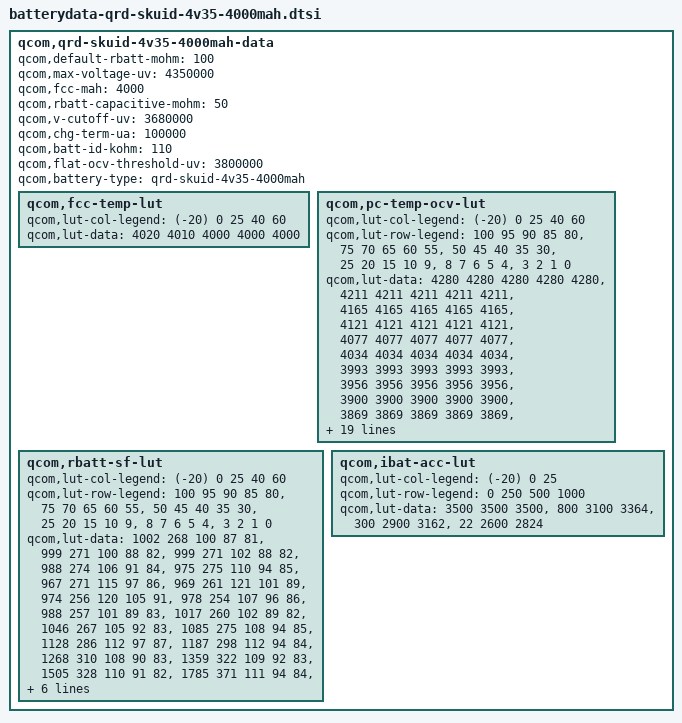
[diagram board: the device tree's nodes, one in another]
/* Copyright (c) 2014, The Linux Foundation. All rights reserved.
 *
 * This program is free software; you can redistribute it and/or modify
 * it under the terms of the GNU General Public License version 2 and
 * only version 2 as published by the Free Software Foundation.
 *
 * This program is distributed in the hope that it will be useful,
 * but WITHOUT ANY WARRANTY; without even the implied warranty of
 * MERCHANTABILITY or FITNESS FOR A PARTICULAR PURPOSE.  See the
 * GNU General Public License for more details.
 */


qcom,qrd-skuid-4v35-4000mah-data {
	qcom,default-rbatt-mohm = <100>;//<188>;
	qcom,max-voltage-uv = <4350000>;
	qcom,fcc-mah = <4000>;
	qcom,rbatt-capacitive-mohm = <50>;
	qcom,v-cutoff-uv = <3680000>;
	qcom,chg-term-ua = <100000>;
	qcom,batt-id-kohm = <110>;
	qcom,flat-ocv-threshold-uv = <3800000>;
	qcom,battery-type = "qrd-skuid-4v35-4000mah";

	qcom,fcc-temp-lut {
		qcom,lut-col-legend = <(-20) 0 25 40 60>;
		qcom,lut-data = <4020 4010 4000 4000 4000>;
	};

	qcom,pc-temp-ocv-lut {
		qcom,lut-col-legend = <(-20) 0 25 40 60>;
		qcom,lut-row-legend = <100 95 90 85 80>,
				<75 70 65 60 55>,
				<50 45 40 35 30>,
				<25 20 15 10 9>,
				<8 7 6 5 4>,
				<3 2 1 0>;
		/*qcom,lut-data = <4280 4280 4280 4280 4280>,
				<4202 4202 4202 4202 4202>,
				<4147 4147 4147 4147 4147>,
				<4095 4095 4095 4095 4095>,
				<4044 4044 4044 4044 4044>,
				<3993 3993 3993 3993 3993>,
				<3946 3946 3946 3946 3946>,
				<3887 3887 3887 3887 3887>,
				<3852 3852 3852 3852 3852>,
				<3815 3815 3815 3815 3815>,
				<3784 3784 3784 3784 3784>,
				<3758 3758 3758 3758 3758>,
				<3735 3735 3735 3735 3735>,
				<3714 3714 3714 3714 3714>,
				<3696 3696 3696 3696 3696>,
				<3681 3681 3681 3681 3681>,
				<3667 3667 3667 3667 3667>,
				<3644 3644 3644 3644 3644>,
				<3613 3613 3613 3613 3613>,
				<3610 3610 3610 3610 3610>,
				<3607 3607 3607 3607 3607>,
				<3605 3605 3605 3605 3605>,
				<3602 3602 3602 3602 3602>,
				<3600 3600 3600 3600 3600>,
				<3593 3593 3593 3593 3593>,
				<3586 3586 3586 3586 3586>,
				<3573 3573 3573 3573 3573>,
				<3549 3549 3549 3549 3549>,
				<3500 3500 3500 3500 3500>;
				*/
			qcom,lut-data = <4280 4280 4280 4280 4280>,
				<4211 4211 4211 4211 4211>,
				<4165 4165 4165 4165 4165>,
				<4121 4121 4121 4121 4121>,
				<4077 4077 4077 4077 4077>,
				<4034 4034 4034 4034 4034>,
				<3993 3993 3993 3993 3993>,
				<3956 3956 3956 3956 3956>,
				<3900 3900 3900 3900 3900>,
				<3869 3869 3869 3869 3869>,
				<3838 3838 3838 3838 3838>,
				<3808 3808 3808 3808 3808>,
				<3782 3782 3782 3782 3782>,
				<3759 3759 3759 3759 3759>,
				<3742 3742 3742 3742 3742>,
				<3723 3723 3723 3723 3723>,
				<3707 3707 3707 3707 3707>,
				<3692 3692 3692 3692 3692>,
				<3679 3679 3679 3679 3679>,
				<3678 3678 3678 3678 3678>,
				<3675 3675 3675 3675 3675>,
				<3673 3673 3673 3673 3673>,
				<3670 3670 3670 3670 3670>,
				<3668 3668 3668 3668 3668>,
				<3665 3665 3665 3665 3665>,
				<3662 3662 3662 3662 3662>,
				<3659 3659 3659 3659 3659>,
				<3654 3654 3654 3654 3654>,
				<3650 3650 3650 3650 3650>;
	};

	qcom,rbatt-sf-lut {
		qcom,lut-col-legend = <(-20) 0 25 40 60>;
		qcom,lut-row-legend = <100 95 90 85 80>,
				<75 70 65 60 55>,
				<50 45 40 35 30>,
				<25 20 15 10 9>,
				<8 7 6 5 4>,
				<3 2 1 0>;
		qcom,lut-data = <1002 268 100 87 81>,
				<999 271 100 88 82>,
				<999 271 102 88 82>,
				<988 274 106 91 84>,
				<975 275 110 94 85>,
				<967 271 115 97 86>,
				<969 261 121 101 89>,
				<974 256 120 105 91>,
				<978 254 107 96 86>,
				<988 257 101 89 83>,
				<1017 260 102 89 82>,
				<1046 267 105 92 83>,
				<1085 275 108 94 85>,
				<1128 286 112 97 87>,
				<1187 298 112 94 84>,
				<1268 310 108 90 83>,
				<1359 322 109 92 83>,
				<1505 328 110 91 82>,
				<1785 371 111 94 84>,
				<1651 331 112 94 84>,
				<1305 342 113 93 84>,
				<1366 351 114 93 83>,
				<1450 364 113 92 82>,
				<1582 373 112 92 84>,
				<1900 398 113 94 85>,
				<2611 443 117 95 86>,
				<4080 519 123 102 93>,
				<8074 696 153 171 149>,
				<30656 4547 9542 7331 6138>;
	};

	qcom,ibat-acc-lut {
		qcom,lut-col-legend = <(-20) 0 25>;
		qcom,lut-row-legend = <0 250 500 1000>;
//		qcom,lut-data = <1937 1937 1933>,
//				<600 1866 1920>,
//				<107 1602 1898>,
//				<11 878 1841>;
//lee
//		qcom,lut-data = <2874 2874 2866>,
//				<1200 2732 2840>,
//				<214 2204 2796>,
//				<22 1500 2682>;
// 1+500m
/*		qcom,lut-data = <3374 3374 3366>,
				<1700 3232 3340>,
				<714 2704 3296>,
				<22 2000 3182>;
*/
// 2
/*		qcom,lut-data = <3900 3900 3900>,
				<1200 3500 3764>,
				<300 3300 3562>,
				<22 3000 3224>;
*/
// 3 
/*		qcom,lut-data = <3800 3800 3800>,
				<1100 3400 3664>,
				<300 3200 3462>,
				<22 2900 3124>;
*/				
// 4
/*		qcom,lut-data = <3700 3700 3700>,
				<1000 3300 3564>,
				<300 3100 3362>,
				<22 2800 3024>;	
*/
// 5
/*		qcom,lut-data = <3600 3600 3600>,
				<900 3200 3464>,
				<300 3000 3262>,
				<22 2700 2924>;
*/				
// 6
		qcom,lut-data = <3500 3500 3500>,
				<800 3100 3364>,
				<300 2900 3162>,
				<22 2600 2824>;
	};
};
